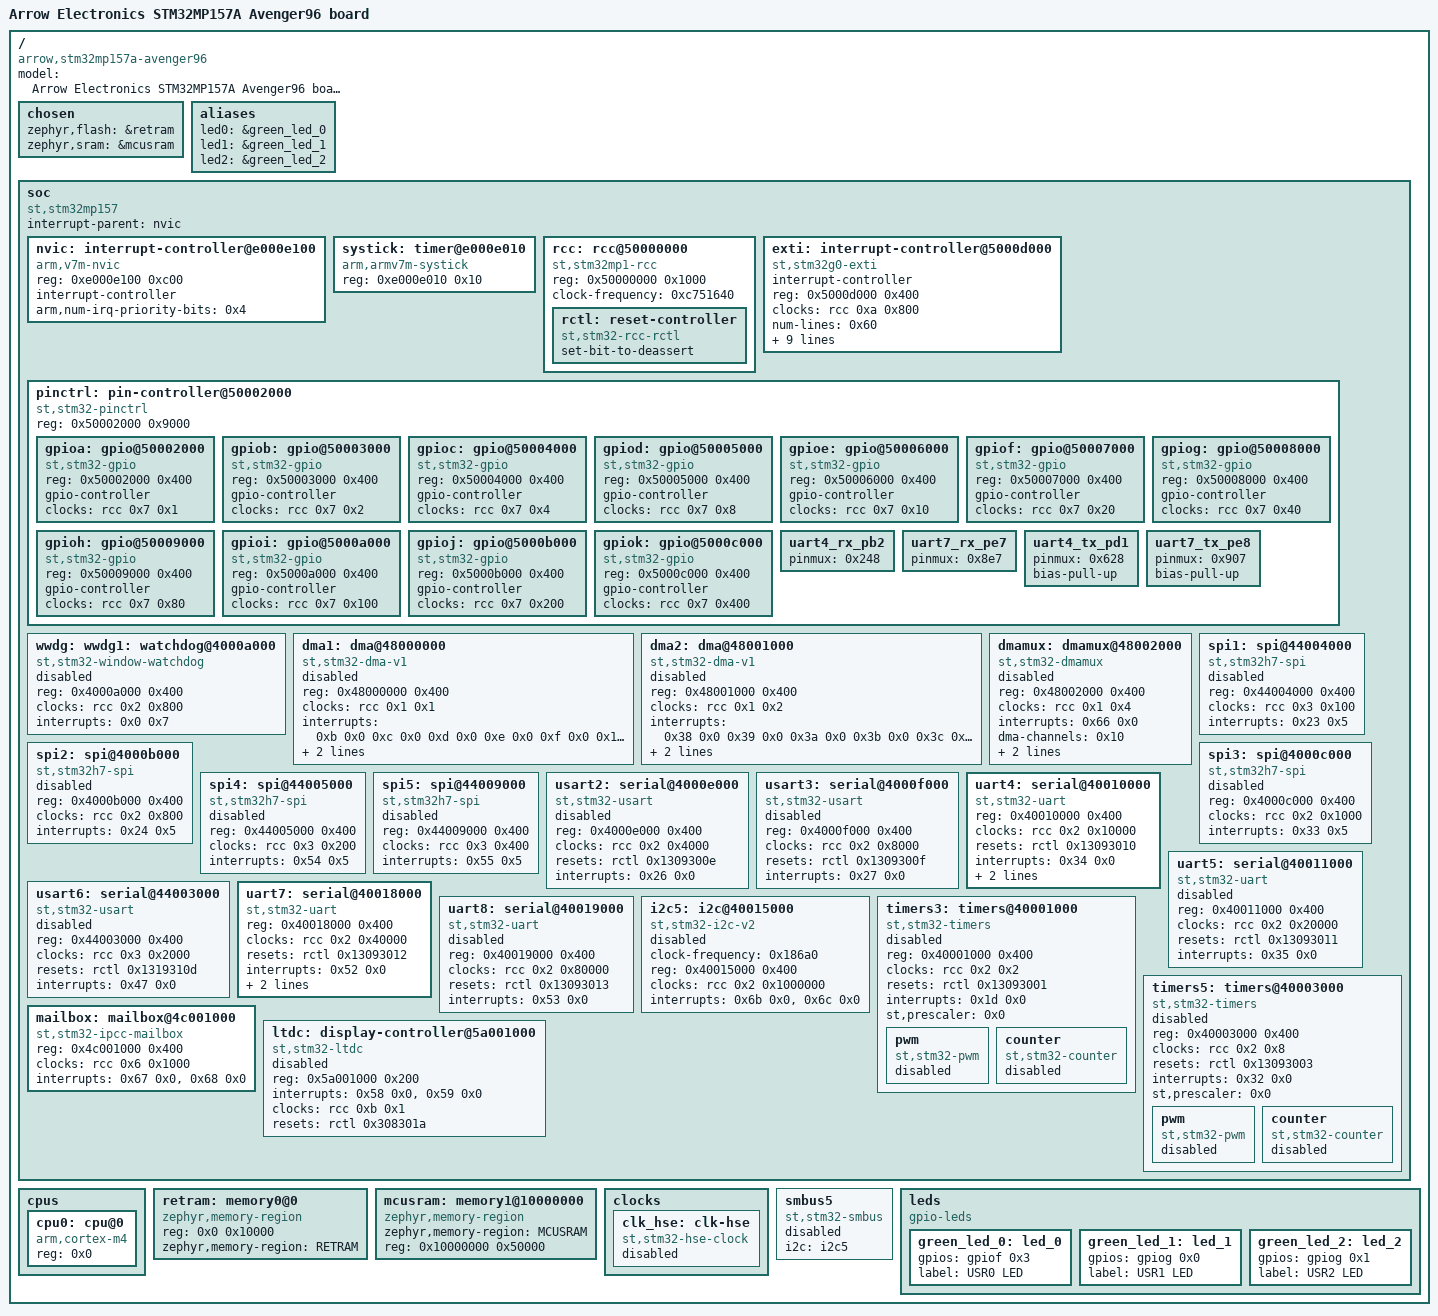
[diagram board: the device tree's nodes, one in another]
/dts-v1/;

/* node '/' defined in zephyr/dts/common/skeleton.dtsi:9 */
/ {
	#address-cells = < 0x1 >;                                /* in zephyr/dts/common/skeleton.dtsi:10 */
	#size-cells = < 0x1 >;                                   /* in zephyr/dts/common/skeleton.dtsi:11 */
	model = "Arrow Electronics STM32MP157A Avenger96 board"; /* in zephyr/boards/96boards/avenger96/96b_avenger96.dts:12 */
	compatible = "arrow,stm32mp157a-avenger96";              /* in zephyr/boards/96boards/avenger96/96b_avenger96.dts:13 */

	/* node '/chosen' defined in zephyr/dts/common/skeleton.dtsi:13 */
	chosen {
		zephyr,flash = &retram; /* in zephyr/boards/96boards/avenger96/96b_avenger96.dts:25 */
		zephyr,sram = &mcusram; /* in zephyr/boards/96boards/avenger96/96b_avenger96.dts:26 */
	};

	/* node '/aliases' defined in zephyr/dts/common/skeleton.dtsi:15 */
	aliases {
		led0 = &green_led_0; /* in zephyr/boards/96boards/avenger96/96b_avenger96.dts:49 */
		led1 = &green_led_1; /* in zephyr/boards/96boards/avenger96/96b_avenger96.dts:50 */
		led2 = &green_led_2; /* in zephyr/boards/96boards/avenger96/96b_avenger96.dts:51 */
	};

	/* node '/soc' defined in zephyr/dts/arm/armv7-m.dtsi:6 */
	soc {
		#address-cells = < 0x1 >;     /* in zephyr/dts/arm/armv7-m.dtsi:7 */
		#size-cells = < 0x1 >;        /* in zephyr/dts/arm/armv7-m.dtsi:8 */
		interrupt-parent = < &nvic >; /* in zephyr/dts/arm/armv7-m.dtsi:10 */
		ranges;                       /* in zephyr/dts/arm/armv7-m.dtsi:11 */
		compatible = "st,stm32mp157",
		             "st,stm32mp1",
		             "simple-bus";    /* in zephyr/dts/arm/st/mp1/stm32mp157.dtsi:55 */

		/* node '/soc/interrupt-controller@e000e100' defined in zephyr/dts/arm/armv7-m.dtsi:13 */
		nvic: interrupt-controller@e000e100 {
			#address-cells = < 0x1 >;            /* in zephyr/dts/arm/armv7-m.dtsi:14 */
			compatible = "arm,v7m-nvic";         /* in zephyr/dts/arm/armv7-m.dtsi:15 */
			reg = < 0xe000e100 0xc00 >;          /* in zephyr/dts/arm/armv7-m.dtsi:16 */
			interrupt-controller;                /* in zephyr/dts/arm/armv7-m.dtsi:17 */
			#interrupt-cells = < 0x2 >;          /* in zephyr/dts/arm/armv7-m.dtsi:18 */
			arm,num-irq-priority-bits = < 0x4 >; /* in zephyr/dts/arm/st/mp1/stm32mp157.dtsi:427 */
			phandle = < 0x1 >;                   /* in zephyr/dts/arm/armv7-m.dtsi:10 */
		};

		/* node '/soc/timer@e000e010' defined in zephyr/dts/arm/armv7-m.dtsi:21 */
		systick: timer@e000e010 {
			compatible = "arm,armv7m-systick"; /* in zephyr/dts/arm/armv7-m.dtsi:22 */
			reg = < 0xe000e010 0x10 >;         /* in zephyr/dts/arm/armv7-m.dtsi:23 */
		};

		/* node '/soc/rcc@50000000' defined in zephyr/dts/arm/st/mp1/stm32mp157.dtsi:57 */
		rcc: rcc@50000000 {
			compatible = "st,stm32mp1-rcc";  /* in zephyr/dts/arm/st/mp1/stm32mp157.dtsi:58 */
			reg = < 0x50000000 0x1000 >;     /* in zephyr/dts/arm/st/mp1/stm32mp157.dtsi:59 */
			#clock-cells = < 0x2 >;          /* in zephyr/dts/arm/st/mp1/stm32mp157.dtsi:60 */
			clock-frequency = < 0xc751640 >; /* in zephyr/boards/96boards/avenger96/96b_avenger96.dts:56 */
			phandle = < 0x2 >;               /* in zephyr/dts/arm/st/mp1/stm32mp157.dtsi:75 */

			/* node '/soc/rcc@50000000/reset-controller' defined in zephyr/dts/arm/st/mp1/stm32mp157.dtsi:62 */
			rctl: reset-controller {
				compatible = "st,stm32-rcc-rctl"; /* in zephyr/dts/arm/st/mp1/stm32mp157.dtsi:63 */
				#reset-cells = < 0x1 >;           /* in zephyr/dts/arm/st/mp1/stm32mp157.dtsi:64 */
				set-bit-to-deassert;              /* in zephyr/dts/arm/st/mp1/stm32mp157.dtsi:65 */
				phandle = < 0x3 >;                /* in zephyr/dts/arm/st/mp1/stm32mp157.dtsi:282 */
			};
		};

		/* node '/soc/interrupt-controller@5000d000' defined in zephyr/dts/arm/st/mp1/stm32mp157.dtsi:69 */
		exti: interrupt-controller@5000d000 {
			compatible = "st,stm32g0-exti",
			             "st,stm32-exti";   /* in zephyr/dts/arm/st/mp1/stm32mp157.dtsi:70 */
			interrupt-controller;           /* in zephyr/dts/arm/st/mp1/stm32mp157.dtsi:71 */
			#interrupt-cells = < 0x1 >;     /* in zephyr/dts/arm/st/mp1/stm32mp157.dtsi:72 */
			#address-cells = < 0x0 >;       /* in zephyr/dts/arm/st/mp1/stm32mp157.dtsi:73 */
			reg = < 0x5000d000 0x400 >;     /* in zephyr/dts/arm/st/mp1/stm32mp157.dtsi:74 */
			clocks = < &rcc 0xa 0x800 >;    /* in zephyr/dts/arm/st/mp1/stm32mp157.dtsi:75 */
			num-lines = < 0x60 >;           /* in zephyr/dts/arm/st/mp1/stm32mp157.dtsi:76 */
			interrupts = < 0x6 0x0 >,
			             < 0x7 0x0 >,
			             < 0x8 0x0 >,
			             < 0x9 0x0 >,
			             < 0xa 0x0 >,
			             < 0x17 0x0 >,
			             < 0x40 0x0 >,
			             < 0x41 0x0 >,
			             < 0x42 0x0 >,
			             < 0x43 0x0 >,
			             < 0x28 0x0 >,
			             < 0x2a 0x0 >,
			             < 0x4c 0x0 >,
			             < 0x4d 0x0 >,
			             < 0x79 0x0 >,
			             < 0x7f 0x0 >;      /* in zephyr/dts/arm/st/mp1/stm32mp157.dtsi:77 */
			interrupt-names = "line0",
			                  "line1",
			                  "line2",
			                  "line3",
			                  "line4",
			                  "line5",
			                  "line6",
			                  "line7",
			                  "line8",
			                  "line9",
			                  "line10",
			                  "line11",
			                  "line12",
			                  "line13",
			                  "line14",
			                  "line15";     /* in zephyr/dts/arm/st/mp1/stm32mp157.dtsi:81 */
			line-ranges = < 0x0 0x1 >,
			              < 0x1 0x1 >,
			              < 0x2 0x1 >,
			              < 0x3 0x1 >,
			              < 0x4 0x1 >,
			              < 0x5 0x1 >,
			              < 0x6 0x1 >,
			              < 0x7 0x1 >,
			              < 0x8 0x1 >,
			              < 0x9 0x1 >,
			              < 0xa 0x1 >,
			              < 0xb 0x1 >,
			              < 0xc 0x1 >,
			              < 0xd 0x1 >,
			              < 0xe 0x1 >,
			              < 0xf 0x1 >;      /* in zephyr/dts/arm/st/mp1/stm32mp157.dtsi:85 */
		};

		/* node '/soc/pin-controller@50002000' defined in zephyr/dts/arm/st/mp1/stm32mp157.dtsi:91 */
		pinctrl: pin-controller@50002000 {
			compatible = "st,stm32-pinctrl"; /* in zephyr/dts/arm/st/mp1/stm32mp157.dtsi:92 */
			reg = < 0x50002000 0x9000 >;     /* in zephyr/dts/arm/st/mp1/stm32mp157.dtsi:93 */
			#address-cells = < 0x1 >;        /* in zephyr/dts/arm/st/mp1/stm32mp157.dtsi:94 */
			#size-cells = < 0x1 >;           /* in zephyr/dts/arm/st/mp1/stm32mp157.dtsi:95 */

			/* node '/soc/pin-controller@50002000/gpio@50002000' defined in zephyr/dts/arm/st/mp1/stm32mp157.dtsi:97 */
			gpioa: gpio@50002000 {
				compatible = "st,stm32-gpio"; /* in zephyr/dts/arm/st/mp1/stm32mp157.dtsi:98 */
				reg = < 0x50002000 0x400 >;   /* in zephyr/dts/arm/st/mp1/stm32mp157.dtsi:99 */
				gpio-controller;              /* in zephyr/dts/arm/st/mp1/stm32mp157.dtsi:100 */
				#gpio-cells = < 0x2 >;        /* in zephyr/dts/arm/st/mp1/stm32mp157.dtsi:101 */
				clocks = < &rcc 0x7 0x1 >;    /* in zephyr/dts/arm/st/mp1/stm32mp157.dtsi:102 */
			};

			/* node '/soc/pin-controller@50002000/gpio@50003000' defined in zephyr/dts/arm/st/mp1/stm32mp157.dtsi:105 */
			gpiob: gpio@50003000 {
				compatible = "st,stm32-gpio"; /* in zephyr/dts/arm/st/mp1/stm32mp157.dtsi:106 */
				reg = < 0x50003000 0x400 >;   /* in zephyr/dts/arm/st/mp1/stm32mp157.dtsi:107 */
				gpio-controller;              /* in zephyr/dts/arm/st/mp1/stm32mp157.dtsi:108 */
				#gpio-cells = < 0x2 >;        /* in zephyr/dts/arm/st/mp1/stm32mp157.dtsi:109 */
				clocks = < &rcc 0x7 0x2 >;    /* in zephyr/dts/arm/st/mp1/stm32mp157.dtsi:110 */
			};

			/* node '/soc/pin-controller@50002000/gpio@50004000' defined in zephyr/dts/arm/st/mp1/stm32mp157.dtsi:113 */
			gpioc: gpio@50004000 {
				compatible = "st,stm32-gpio"; /* in zephyr/dts/arm/st/mp1/stm32mp157.dtsi:114 */
				reg = < 0x50004000 0x400 >;   /* in zephyr/dts/arm/st/mp1/stm32mp157.dtsi:115 */
				gpio-controller;              /* in zephyr/dts/arm/st/mp1/stm32mp157.dtsi:116 */
				#gpio-cells = < 0x2 >;        /* in zephyr/dts/arm/st/mp1/stm32mp157.dtsi:117 */
				clocks = < &rcc 0x7 0x4 >;    /* in zephyr/dts/arm/st/mp1/stm32mp157.dtsi:118 */
			};

			/* node '/soc/pin-controller@50002000/gpio@50005000' defined in zephyr/dts/arm/st/mp1/stm32mp157.dtsi:121 */
			gpiod: gpio@50005000 {
				compatible = "st,stm32-gpio"; /* in zephyr/dts/arm/st/mp1/stm32mp157.dtsi:122 */
				reg = < 0x50005000 0x400 >;   /* in zephyr/dts/arm/st/mp1/stm32mp157.dtsi:123 */
				gpio-controller;              /* in zephyr/dts/arm/st/mp1/stm32mp157.dtsi:124 */
				#gpio-cells = < 0x2 >;        /* in zephyr/dts/arm/st/mp1/stm32mp157.dtsi:125 */
				clocks = < &rcc 0x7 0x8 >;    /* in zephyr/dts/arm/st/mp1/stm32mp157.dtsi:126 */
			};

			/* node '/soc/pin-controller@50002000/gpio@50006000' defined in zephyr/dts/arm/st/mp1/stm32mp157.dtsi:129 */
			gpioe: gpio@50006000 {
				compatible = "st,stm32-gpio"; /* in zephyr/dts/arm/st/mp1/stm32mp157.dtsi:130 */
				reg = < 0x50006000 0x400 >;   /* in zephyr/dts/arm/st/mp1/stm32mp157.dtsi:131 */
				gpio-controller;              /* in zephyr/dts/arm/st/mp1/stm32mp157.dtsi:132 */
				#gpio-cells = < 0x2 >;        /* in zephyr/dts/arm/st/mp1/stm32mp157.dtsi:133 */
				clocks = < &rcc 0x7 0x10 >;   /* in zephyr/dts/arm/st/mp1/stm32mp157.dtsi:134 */
			};

			/* node '/soc/pin-controller@50002000/gpio@50007000' defined in zephyr/dts/arm/st/mp1/stm32mp157.dtsi:137 */
			gpiof: gpio@50007000 {
				compatible = "st,stm32-gpio"; /* in zephyr/dts/arm/st/mp1/stm32mp157.dtsi:138 */
				reg = < 0x50007000 0x400 >;   /* in zephyr/dts/arm/st/mp1/stm32mp157.dtsi:139 */
				gpio-controller;              /* in zephyr/dts/arm/st/mp1/stm32mp157.dtsi:140 */
				#gpio-cells = < 0x2 >;        /* in zephyr/dts/arm/st/mp1/stm32mp157.dtsi:141 */
				clocks = < &rcc 0x7 0x20 >;   /* in zephyr/dts/arm/st/mp1/stm32mp157.dtsi:142 */
				phandle = < 0x9 >;            /* in zephyr/boards/96boards/avenger96/96b_avenger96.dts:33 */
			};

			/* node '/soc/pin-controller@50002000/gpio@50008000' defined in zephyr/dts/arm/st/mp1/stm32mp157.dtsi:145 */
			gpiog: gpio@50008000 {
				compatible = "st,stm32-gpio"; /* in zephyr/dts/arm/st/mp1/stm32mp157.dtsi:146 */
				reg = < 0x50008000 0x400 >;   /* in zephyr/dts/arm/st/mp1/stm32mp157.dtsi:147 */
				gpio-controller;              /* in zephyr/dts/arm/st/mp1/stm32mp157.dtsi:148 */
				#gpio-cells = < 0x2 >;        /* in zephyr/dts/arm/st/mp1/stm32mp157.dtsi:149 */
				clocks = < &rcc 0x7 0x40 >;   /* in zephyr/dts/arm/st/mp1/stm32mp157.dtsi:150 */
				phandle = < 0xa >;            /* in zephyr/boards/96boards/avenger96/96b_avenger96.dts:38 */
			};

			/* node '/soc/pin-controller@50002000/gpio@50009000' defined in zephyr/dts/arm/st/mp1/stm32mp157.dtsi:153 */
			gpioh: gpio@50009000 {
				compatible = "st,stm32-gpio"; /* in zephyr/dts/arm/st/mp1/stm32mp157.dtsi:154 */
				reg = < 0x50009000 0x400 >;   /* in zephyr/dts/arm/st/mp1/stm32mp157.dtsi:155 */
				gpio-controller;              /* in zephyr/dts/arm/st/mp1/stm32mp157.dtsi:156 */
				#gpio-cells = < 0x2 >;        /* in zephyr/dts/arm/st/mp1/stm32mp157.dtsi:157 */
				clocks = < &rcc 0x7 0x80 >;   /* in zephyr/dts/arm/st/mp1/stm32mp157.dtsi:158 */
			};

			/* node '/soc/pin-controller@50002000/gpio@5000a000' defined in zephyr/dts/arm/st/mp1/stm32mp157.dtsi:161 */
			gpioi: gpio@5000a000 {
				compatible = "st,stm32-gpio"; /* in zephyr/dts/arm/st/mp1/stm32mp157.dtsi:162 */
				reg = < 0x5000a000 0x400 >;   /* in zephyr/dts/arm/st/mp1/stm32mp157.dtsi:163 */
				gpio-controller;              /* in zephyr/dts/arm/st/mp1/stm32mp157.dtsi:164 */
				#gpio-cells = < 0x2 >;        /* in zephyr/dts/arm/st/mp1/stm32mp157.dtsi:165 */
				clocks = < &rcc 0x7 0x100 >;  /* in zephyr/dts/arm/st/mp1/stm32mp157.dtsi:166 */
			};

			/* node '/soc/pin-controller@50002000/gpio@5000b000' defined in zephyr/dts/arm/st/mp1/stm32mp157.dtsi:169 */
			gpioj: gpio@5000b000 {
				compatible = "st,stm32-gpio"; /* in zephyr/dts/arm/st/mp1/stm32mp157.dtsi:170 */
				reg = < 0x5000b000 0x400 >;   /* in zephyr/dts/arm/st/mp1/stm32mp157.dtsi:171 */
				gpio-controller;              /* in zephyr/dts/arm/st/mp1/stm32mp157.dtsi:172 */
				#gpio-cells = < 0x2 >;        /* in zephyr/dts/arm/st/mp1/stm32mp157.dtsi:173 */
				clocks = < &rcc 0x7 0x200 >;  /* in zephyr/dts/arm/st/mp1/stm32mp157.dtsi:174 */
			};

			/* node '/soc/pin-controller@50002000/gpio@5000c000' defined in zephyr/dts/arm/st/mp1/stm32mp157.dtsi:177 */
			gpiok: gpio@5000c000 {
				compatible = "st,stm32-gpio"; /* in zephyr/dts/arm/st/mp1/stm32mp157.dtsi:178 */
				reg = < 0x5000c000 0x400 >;   /* in zephyr/dts/arm/st/mp1/stm32mp157.dtsi:179 */
				gpio-controller;              /* in zephyr/dts/arm/st/mp1/stm32mp157.dtsi:180 */
				#gpio-cells = < 0x2 >;        /* in zephyr/dts/arm/st/mp1/stm32mp157.dtsi:181 */
				clocks = < &rcc 0x7 0x400 >;  /* in zephyr/dts/arm/st/mp1/stm32mp157.dtsi:182 */
			};

			/* node '/soc/pin-controller@50002000/uart4_rx_pb2' defined in modules/hal/stm32/dts/st/mp1/stm32mp157aacx-pinctrl.dtsi:5042 */
			uart4_rx_pb2: uart4_rx_pb2 {
				pinmux = < 0x248 >; /* in modules/hal/stm32/dts/st/mp1/stm32mp157aacx-pinctrl.dtsi:5043 */
				phandle = < 0x5 >;  /* in zephyr/boards/96boards/avenger96/96b_avenger96.dts:64 */
			};

			/* node '/soc/pin-controller@50002000/uart7_rx_pe7' defined in modules/hal/stm32/dts/st/mp1/stm32mp157aacx-pinctrl.dtsi:5098 */
			uart7_rx_pe7: uart7_rx_pe7 {
				pinmux = < 0x8e7 >; /* in modules/hal/stm32/dts/st/mp1/stm32mp157aacx-pinctrl.dtsi:5099 */
				phandle = < 0x7 >;  /* in zephyr/boards/96boards/avenger96/96b_avenger96.dts:71 */
			};

			/* node '/soc/pin-controller@50002000/uart4_tx_pd1' defined in modules/hal/stm32/dts/st/mp1/stm32mp157aacx-pinctrl.dtsi:5202 */
			uart4_tx_pd1: uart4_tx_pd1 {
				pinmux = < 0x628 >; /* in modules/hal/stm32/dts/st/mp1/stm32mp157aacx-pinctrl.dtsi:5203 */
				bias-pull-up;       /* in modules/hal/stm32/dts/st/mp1/stm32mp157aacx-pinctrl.dtsi:5204 */
				phandle = < 0x4 >;  /* in zephyr/boards/96boards/avenger96/96b_avenger96.dts:64 */
			};

			/* node '/soc/pin-controller@50002000/uart7_tx_pe8' defined in modules/hal/stm32/dts/st/mp1/stm32mp157aacx-pinctrl.dtsi:5252 */
			uart7_tx_pe8: uart7_tx_pe8 {
				pinmux = < 0x907 >; /* in modules/hal/stm32/dts/st/mp1/stm32mp157aacx-pinctrl.dtsi:5253 */
				bias-pull-up;       /* in modules/hal/stm32/dts/st/mp1/stm32mp157aacx-pinctrl.dtsi:5254 */
				phandle = < 0x6 >;  /* in zephyr/boards/96boards/avenger96/96b_avenger96.dts:71 */
			};
		};

		/* node '/soc/watchdog@4000a000' defined in zephyr/dts/arm/st/mp1/stm32mp157.dtsi:186 */
		wwdg: wwdg1: watchdog@4000a000 {
			compatible = "st,stm32-window-watchdog"; /* in zephyr/dts/arm/st/mp1/stm32mp157.dtsi:187 */
			reg = < 0x4000a000 0x400 >;              /* in zephyr/dts/arm/st/mp1/stm32mp157.dtsi:188 */
			clocks = < &rcc 0x2 0x800 >;             /* in zephyr/dts/arm/st/mp1/stm32mp157.dtsi:189 */
			interrupts = < 0x0 0x7 >;                /* in zephyr/dts/arm/st/mp1/stm32mp157.dtsi:190 */
			status = "disabled";                     /* in zephyr/dts/arm/st/mp1/stm32mp157.dtsi:191 */
		};

		/* node '/soc/dma@48000000' defined in zephyr/dts/arm/st/mp1/stm32mp157.dtsi:194 */
		dma1: dma@48000000 {
			compatible = "st,stm32-dma-v1";                                                      /* in zephyr/dts/arm/st/mp1/stm32mp157.dtsi:195 */
			#dma-cells = < 0x4 >;                                                                /* in zephyr/dts/arm/st/mp1/stm32mp157.dtsi:196 */
			reg = < 0x48000000 0x400 >;                                                          /* in zephyr/dts/arm/st/mp1/stm32mp157.dtsi:197 */
			clocks = < &rcc 0x1 0x1 >;                                                           /* in zephyr/dts/arm/st/mp1/stm32mp157.dtsi:198 */
			interrupts = < 0xb 0x0 0xc 0x0 0xd 0x0 0xe 0x0 0xf 0x0 0x10 0x0 0x11 0x0 0x2f 0x0 >; /* in zephyr/dts/arm/st/mp1/stm32mp157.dtsi:199 */
			dma-offset = < 0x0 >;                                                                /* in zephyr/dts/arm/st/mp1/stm32mp157.dtsi:200 */
			dma-requests = < 0x8 >;                                                              /* in zephyr/dts/arm/st/mp1/stm32mp157.dtsi:201 */
			status = "disabled";                                                                 /* in zephyr/dts/arm/st/mp1/stm32mp157.dtsi:202 */
		};

		/* node '/soc/dma@48001000' defined in zephyr/dts/arm/st/mp1/stm32mp157.dtsi:205 */
		dma2: dma@48001000 {
			compatible = "st,stm32-dma-v1";                                                           /* in zephyr/dts/arm/st/mp1/stm32mp157.dtsi:206 */
			#dma-cells = < 0x4 >;                                                                     /* in zephyr/dts/arm/st/mp1/stm32mp157.dtsi:207 */
			reg = < 0x48001000 0x400 >;                                                               /* in zephyr/dts/arm/st/mp1/stm32mp157.dtsi:208 */
			clocks = < &rcc 0x1 0x2 >;                                                                /* in zephyr/dts/arm/st/mp1/stm32mp157.dtsi:209 */
			interrupts = < 0x38 0x0 0x39 0x0 0x3a 0x0 0x3b 0x0 0x3c 0x0 0x44 0x0 0x45 0x0 0x46 0x0 >; /* in zephyr/dts/arm/st/mp1/stm32mp157.dtsi:210 */
			dma-offset = < 0x8 >;                                                                     /* in zephyr/dts/arm/st/mp1/stm32mp157.dtsi:211 */
			dma-requests = < 0x8 >;                                                                   /* in zephyr/dts/arm/st/mp1/stm32mp157.dtsi:212 */
			status = "disabled";                                                                      /* in zephyr/dts/arm/st/mp1/stm32mp157.dtsi:213 */
		};

		/* node '/soc/dmamux@48002000' defined in zephyr/dts/arm/st/mp1/stm32mp157.dtsi:216 */
		dmamux: dmamux@48002000 {
			compatible = "st,stm32-dmamux"; /* in zephyr/dts/arm/st/mp1/stm32mp157.dtsi:217 */
			#dma-cells = < 0x3 >;           /* in zephyr/dts/arm/st/mp1/stm32mp157.dtsi:218 */
			reg = < 0x48002000 0x400 >;     /* in zephyr/dts/arm/st/mp1/stm32mp157.dtsi:219 */
			clocks = < &rcc 0x1 0x4 >;      /* in zephyr/dts/arm/st/mp1/stm32mp157.dtsi:220 */
			interrupts = < 0x66 0x0 >;      /* in zephyr/dts/arm/st/mp1/stm32mp157.dtsi:221 */
			dma-channels = < 0x10 >;        /* in zephyr/dts/arm/st/mp1/stm32mp157.dtsi:222 */
			dma-generators = < 0x8 >;       /* in zephyr/dts/arm/st/mp1/stm32mp157.dtsi:223 */
			dma-requests = < 0x6c >;        /* in zephyr/dts/arm/st/mp1/stm32mp157.dtsi:224 */
			status = "disabled";            /* in zephyr/dts/arm/st/mp1/stm32mp157.dtsi:225 */
		};

		/* node '/soc/spi@44004000' defined in zephyr/dts/arm/st/mp1/stm32mp157.dtsi:228 */
		spi1: spi@44004000 {
			compatible = "st,stm32h7-spi",
			             "st,stm32-spi-fifo",
			             "st,stm32-spi";      /* in zephyr/dts/arm/st/mp1/stm32mp157.dtsi:229 */
			reg = < 0x44004000 0x400 >;       /* in zephyr/dts/arm/st/mp1/stm32mp157.dtsi:230 */
			#address-cells = < 0x1 >;         /* in zephyr/dts/arm/st/mp1/stm32mp157.dtsi:231 */
			#size-cells = < 0x0 >;            /* in zephyr/dts/arm/st/mp1/stm32mp157.dtsi:232 */
			clocks = < &rcc 0x3 0x100 >;      /* in zephyr/dts/arm/st/mp1/stm32mp157.dtsi:233 */
			interrupts = < 0x23 0x5 >;        /* in zephyr/dts/arm/st/mp1/stm32mp157.dtsi:234 */
			status = "disabled";              /* in zephyr/dts/arm/st/mp1/stm32mp157.dtsi:235 */
		};

		/* node '/soc/spi@4000b000' defined in zephyr/dts/arm/st/mp1/stm32mp157.dtsi:238 */
		spi2: spi@4000b000 {
			compatible = "st,stm32h7-spi",
			             "st,stm32-spi-fifo",
			             "st,stm32-spi";      /* in zephyr/dts/arm/st/mp1/stm32mp157.dtsi:239 */
			reg = < 0x4000b000 0x400 >;       /* in zephyr/dts/arm/st/mp1/stm32mp157.dtsi:240 */
			#address-cells = < 0x1 >;         /* in zephyr/dts/arm/st/mp1/stm32mp157.dtsi:241 */
			#size-cells = < 0x0 >;            /* in zephyr/dts/arm/st/mp1/stm32mp157.dtsi:242 */
			clocks = < &rcc 0x2 0x800 >;      /* in zephyr/dts/arm/st/mp1/stm32mp157.dtsi:243 */
			interrupts = < 0x24 0x5 >;        /* in zephyr/dts/arm/st/mp1/stm32mp157.dtsi:244 */
			status = "disabled";              /* in zephyr/dts/arm/st/mp1/stm32mp157.dtsi:245 */
		};

		/* node '/soc/spi@4000c000' defined in zephyr/dts/arm/st/mp1/stm32mp157.dtsi:248 */
		spi3: spi@4000c000 {
			compatible = "st,stm32h7-spi",
			             "st,stm32-spi-fifo",
			             "st,stm32-spi";      /* in zephyr/dts/arm/st/mp1/stm32mp157.dtsi:249 */
			reg = < 0x4000c000 0x400 >;       /* in zephyr/dts/arm/st/mp1/stm32mp157.dtsi:250 */
			#address-cells = < 0x1 >;         /* in zephyr/dts/arm/st/mp1/stm32mp157.dtsi:251 */
			#size-cells = < 0x0 >;            /* in zephyr/dts/arm/st/mp1/stm32mp157.dtsi:252 */
			clocks = < &rcc 0x2 0x1000 >;     /* in zephyr/dts/arm/st/mp1/stm32mp157.dtsi:253 */
			interrupts = < 0x33 0x5 >;        /* in zephyr/dts/arm/st/mp1/stm32mp157.dtsi:254 */
			status = "disabled";              /* in zephyr/dts/arm/st/mp1/stm32mp157.dtsi:255 */
		};

		/* node '/soc/spi@44005000' defined in zephyr/dts/arm/st/mp1/stm32mp157.dtsi:258 */
		spi4: spi@44005000 {
			compatible = "st,stm32h7-spi",
			             "st,stm32-spi-fifo",
			             "st,stm32-spi";      /* in zephyr/dts/arm/st/mp1/stm32mp157.dtsi:259 */
			reg = < 0x44005000 0x400 >;       /* in zephyr/dts/arm/st/mp1/stm32mp157.dtsi:260 */
			#address-cells = < 0x1 >;         /* in zephyr/dts/arm/st/mp1/stm32mp157.dtsi:261 */
			#size-cells = < 0x0 >;            /* in zephyr/dts/arm/st/mp1/stm32mp157.dtsi:262 */
			clocks = < &rcc 0x3 0x200 >;      /* in zephyr/dts/arm/st/mp1/stm32mp157.dtsi:263 */
			interrupts = < 0x54 0x5 >;        /* in zephyr/dts/arm/st/mp1/stm32mp157.dtsi:264 */
			status = "disabled";              /* in zephyr/dts/arm/st/mp1/stm32mp157.dtsi:265 */
		};

		/* node '/soc/spi@44009000' defined in zephyr/dts/arm/st/mp1/stm32mp157.dtsi:268 */
		spi5: spi@44009000 {
			compatible = "st,stm32h7-spi",
			             "st,stm32-spi-fifo",
			             "st,stm32-spi";      /* in zephyr/dts/arm/st/mp1/stm32mp157.dtsi:269 */
			reg = < 0x44009000 0x400 >;       /* in zephyr/dts/arm/st/mp1/stm32mp157.dtsi:270 */
			#address-cells = < 0x1 >;         /* in zephyr/dts/arm/st/mp1/stm32mp157.dtsi:271 */
			#size-cells = < 0x0 >;            /* in zephyr/dts/arm/st/mp1/stm32mp157.dtsi:272 */
			clocks = < &rcc 0x3 0x400 >;      /* in zephyr/dts/arm/st/mp1/stm32mp157.dtsi:273 */
			interrupts = < 0x55 0x5 >;        /* in zephyr/dts/arm/st/mp1/stm32mp157.dtsi:274 */
			status = "disabled";              /* in zephyr/dts/arm/st/mp1/stm32mp157.dtsi:275 */
		};

		/* node '/soc/serial@4000e000' defined in zephyr/dts/arm/st/mp1/stm32mp157.dtsi:278 */
		usart2: serial@4000e000 {
			compatible = "st,stm32-usart",
			             "st,stm32-uart";  /* in zephyr/dts/arm/st/mp1/stm32mp157.dtsi:279 */
			reg = < 0x4000e000 0x400 >;    /* in zephyr/dts/arm/st/mp1/stm32mp157.dtsi:280 */
			clocks = < &rcc 0x2 0x4000 >;  /* in zephyr/dts/arm/st/mp1/stm32mp157.dtsi:281 */
			resets = < &rctl 0x1309300e >; /* in zephyr/dts/arm/st/mp1/stm32mp157.dtsi:282 */
			interrupts = < 0x26 0x0 >;     /* in zephyr/dts/arm/st/mp1/stm32mp157.dtsi:283 */
			status = "disabled";           /* in zephyr/dts/arm/st/mp1/stm32mp157.dtsi:284 */
		};

		/* node '/soc/serial@4000f000' defined in zephyr/dts/arm/st/mp1/stm32mp157.dtsi:287 */
		usart3: serial@4000f000 {
			compatible = "st,stm32-usart",
			             "st,stm32-uart";  /* in zephyr/dts/arm/st/mp1/stm32mp157.dtsi:288 */
			reg = < 0x4000f000 0x400 >;    /* in zephyr/dts/arm/st/mp1/stm32mp157.dtsi:289 */
			clocks = < &rcc 0x2 0x8000 >;  /* in zephyr/dts/arm/st/mp1/stm32mp157.dtsi:290 */
			resets = < &rctl 0x1309300f >; /* in zephyr/dts/arm/st/mp1/stm32mp157.dtsi:291 */
			interrupts = < 0x27 0x0 >;     /* in zephyr/dts/arm/st/mp1/stm32mp157.dtsi:292 */
			status = "disabled";           /* in zephyr/dts/arm/st/mp1/stm32mp157.dtsi:293 */
		};

		/* node '/soc/serial@40010000' defined in zephyr/dts/arm/st/mp1/stm32mp157.dtsi:296 */
		uart4: serial@40010000 {
			compatible = "st,stm32-uart";                /* in zephyr/dts/arm/st/mp1/stm32mp157.dtsi:297 */
			reg = < 0x40010000 0x400 >;                  /* in zephyr/dts/arm/st/mp1/stm32mp157.dtsi:298 */
			clocks = < &rcc 0x2 0x10000 >;               /* in zephyr/dts/arm/st/mp1/stm32mp157.dtsi:299 */
			resets = < &rctl 0x13093010 >;               /* in zephyr/dts/arm/st/mp1/stm32mp157.dtsi:300 */
			interrupts = < 0x34 0x0 >;                   /* in zephyr/dts/arm/st/mp1/stm32mp157.dtsi:301 */
			pinctrl-0 = < &uart4_tx_pd1 &uart4_rx_pb2 >; /* in zephyr/boards/96boards/avenger96/96b_avenger96.dts:64 */
			pinctrl-names = "default";                   /* in zephyr/boards/96boards/avenger96/96b_avenger96.dts:65 */
			current-speed = < 0x1c200 >;                 /* in zephyr/boards/96boards/avenger96/96b_avenger96.dts:66 */
			status = "okay";                             /* in zephyr/boards/96boards/avenger96/96b_avenger96.dts:67 */
		};

		/* node '/soc/serial@40011000' defined in zephyr/dts/arm/st/mp1/stm32mp157.dtsi:305 */
		uart5: serial@40011000 {
			compatible = "st,stm32-uart";  /* in zephyr/dts/arm/st/mp1/stm32mp157.dtsi:306 */
			reg = < 0x40011000 0x400 >;    /* in zephyr/dts/arm/st/mp1/stm32mp157.dtsi:307 */
			clocks = < &rcc 0x2 0x20000 >; /* in zephyr/dts/arm/st/mp1/stm32mp157.dtsi:308 */
			resets = < &rctl 0x13093011 >; /* in zephyr/dts/arm/st/mp1/stm32mp157.dtsi:309 */
			interrupts = < 0x35 0x0 >;     /* in zephyr/dts/arm/st/mp1/stm32mp157.dtsi:310 */
			status = "disabled";           /* in zephyr/dts/arm/st/mp1/stm32mp157.dtsi:311 */
		};

		/* node '/soc/serial@44003000' defined in zephyr/dts/arm/st/mp1/stm32mp157.dtsi:314 */
		usart6: serial@44003000 {
			compatible = "st,stm32-usart",
			             "st,stm32-uart";  /* in zephyr/dts/arm/st/mp1/stm32mp157.dtsi:315 */
			reg = < 0x44003000 0x400 >;    /* in zephyr/dts/arm/st/mp1/stm32mp157.dtsi:316 */
			clocks = < &rcc 0x3 0x2000 >;  /* in zephyr/dts/arm/st/mp1/stm32mp157.dtsi:317 */
			resets = < &rctl 0x1319310d >; /* in zephyr/dts/arm/st/mp1/stm32mp157.dtsi:318 */
			interrupts = < 0x47 0x0 >;     /* in zephyr/dts/arm/st/mp1/stm32mp157.dtsi:319 */
			status = "disabled";           /* in zephyr/dts/arm/st/mp1/stm32mp157.dtsi:320 */
		};

		/* node '/soc/serial@40018000' defined in zephyr/dts/arm/st/mp1/stm32mp157.dtsi:323 */
		uart7: serial@40018000 {
			compatible = "st,stm32-uart";                /* in zephyr/dts/arm/st/mp1/stm32mp157.dtsi:324 */
			reg = < 0x40018000 0x400 >;                  /* in zephyr/dts/arm/st/mp1/stm32mp157.dtsi:325 */
			clocks = < &rcc 0x2 0x40000 >;               /* in zephyr/dts/arm/st/mp1/stm32mp157.dtsi:326 */
			resets = < &rctl 0x13093012 >;               /* in zephyr/dts/arm/st/mp1/stm32mp157.dtsi:327 */
			interrupts = < 0x52 0x0 >;                   /* in zephyr/dts/arm/st/mp1/stm32mp157.dtsi:328 */
			pinctrl-0 = < &uart7_tx_pe8 &uart7_rx_pe7 >; /* in zephyr/boards/96boards/avenger96/96b_avenger96.dts:71 */
			pinctrl-names = "default";                   /* in zephyr/boards/96boards/avenger96/96b_avenger96.dts:72 */
			current-speed = < 0x1c200 >;                 /* in zephyr/boards/96boards/avenger96/96b_avenger96.dts:73 */
			status = "okay";                             /* in zephyr/boards/96boards/avenger96/96b_avenger96.dts:74 */
		};

		/* node '/soc/serial@40019000' defined in zephyr/dts/arm/st/mp1/stm32mp157.dtsi:332 */
		uart8: serial@40019000 {
			compatible = "st,stm32-uart";  /* in zephyr/dts/arm/st/mp1/stm32mp157.dtsi:333 */
			reg = < 0x40019000 0x400 >;    /* in zephyr/dts/arm/st/mp1/stm32mp157.dtsi:334 */
			clocks = < &rcc 0x2 0x80000 >; /* in zephyr/dts/arm/st/mp1/stm32mp157.dtsi:335 */
			resets = < &rctl 0x13093013 >; /* in zephyr/dts/arm/st/mp1/stm32mp157.dtsi:336 */
			interrupts = < 0x53 0x0 >;     /* in zephyr/dts/arm/st/mp1/stm32mp157.dtsi:337 */
			status = "disabled";           /* in zephyr/dts/arm/st/mp1/stm32mp157.dtsi:338 */
		};

		/* node '/soc/i2c@40015000' defined in zephyr/dts/arm/st/mp1/stm32mp157.dtsi:341 */
		i2c5: i2c@40015000 {
			compatible = "st,stm32-i2c-v2";  /* in zephyr/dts/arm/st/mp1/stm32mp157.dtsi:342 */
			clock-frequency = < 0x186a0 >;   /* in zephyr/dts/arm/st/mp1/stm32mp157.dtsi:343 */
			reg = < 0x40015000 0x400 >;      /* in zephyr/dts/arm/st/mp1/stm32mp157.dtsi:344 */
			#address-cells = < 0x1 >;        /* in zephyr/dts/arm/st/mp1/stm32mp157.dtsi:345 */
			#size-cells = < 0x0 >;           /* in zephyr/dts/arm/st/mp1/stm32mp157.dtsi:346 */
			clocks = < &rcc 0x2 0x1000000 >; /* in zephyr/dts/arm/st/mp1/stm32mp157.dtsi:347 */
			interrupt-names = "event",
			                  "error";       /* in zephyr/dts/arm/st/mp1/stm32mp157.dtsi:348 */
			interrupts = < 0x6b 0x0 >,
			             < 0x6c 0x0 >;       /* in zephyr/dts/arm/st/mp1/stm32mp157.dtsi:349 */
			status = "disabled";             /* in zephyr/dts/arm/st/mp1/stm32mp157.dtsi:350 */
			phandle = < 0x8 >;               /* in zephyr/dts/arm/st/mp1/stm32mp157.dtsi:421 */
		};

		/* node '/soc/timers@40001000' defined in zephyr/dts/arm/st/mp1/stm32mp157.dtsi:353 */
		timers3: timers@40001000 {
			compatible = "st,stm32-timers"; /* in zephyr/dts/arm/st/mp1/stm32mp157.dtsi:354 */
			reg = < 0x40001000 0x400 >;     /* in zephyr/dts/arm/st/mp1/stm32mp157.dtsi:355 */
			clocks = < &rcc 0x2 0x2 >;      /* in zephyr/dts/arm/st/mp1/stm32mp157.dtsi:356 */
			resets = < &rctl 0x13093001 >;  /* in zephyr/dts/arm/st/mp1/stm32mp157.dtsi:357 */
			interrupts = < 0x1d 0x0 >;      /* in zephyr/dts/arm/st/mp1/stm32mp157.dtsi:358 */
			interrupt-names = "global";     /* in zephyr/dts/arm/st/mp1/stm32mp157.dtsi:359 */
			st,prescaler = < 0x0 >;         /* in zephyr/dts/arm/st/mp1/stm32mp157.dtsi:360 */
			status = "disabled";            /* in zephyr/dts/arm/st/mp1/stm32mp157.dtsi:361 */

			/* node '/soc/timers@40001000/pwm' defined in zephyr/dts/arm/st/mp1/stm32mp157.dtsi:363 */
			pwm {
				compatible = "st,stm32-pwm"; /* in zephyr/dts/arm/st/mp1/stm32mp157.dtsi:364 */
				status = "disabled";         /* in zephyr/dts/arm/st/mp1/stm32mp157.dtsi:365 */
				#pwm-cells = < 0x3 >;        /* in zephyr/dts/arm/st/mp1/stm32mp157.dtsi:366 */
			};

			/* node '/soc/timers@40001000/counter' defined in zephyr/dts/arm/st/mp1/stm32mp157.dtsi:369 */
			counter {
				compatible = "st,stm32-counter"; /* in zephyr/dts/arm/st/mp1/stm32mp157.dtsi:370 */
				status = "disabled";             /* in zephyr/dts/arm/st/mp1/stm32mp157.dtsi:371 */
			};
		};

		/* node '/soc/timers@40003000' defined in zephyr/dts/arm/st/mp1/stm32mp157.dtsi:375 */
		timers5: timers@40003000 {
			compatible = "st,stm32-timers"; /* in zephyr/dts/arm/st/mp1/stm32mp157.dtsi:376 */
			reg = < 0x40003000 0x400 >;     /* in zephyr/dts/arm/st/mp1/stm32mp157.dtsi:377 */
			clocks = < &rcc 0x2 0x8 >;      /* in zephyr/dts/arm/st/mp1/stm32mp157.dtsi:378 */
			resets = < &rctl 0x13093003 >;  /* in zephyr/dts/arm/st/mp1/stm32mp157.dtsi:379 */
			interrupts = < 0x32 0x0 >;      /* in zephyr/dts/arm/st/mp1/stm32mp157.dtsi:380 */
			interrupt-names = "global";     /* in zephyr/dts/arm/st/mp1/stm32mp157.dtsi:381 */
			st,prescaler = < 0x0 >;         /* in zephyr/dts/arm/st/mp1/stm32mp157.dtsi:382 */
			status = "disabled";            /* in zephyr/dts/arm/st/mp1/stm32mp157.dtsi:383 */

			/* node '/soc/timers@40003000/pwm' defined in zephyr/dts/arm/st/mp1/stm32mp157.dtsi:385 */
			pwm {
				compatible = "st,stm32-pwm"; /* in zephyr/dts/arm/st/mp1/stm32mp157.dtsi:386 */
				status = "disabled";         /* in zephyr/dts/arm/st/mp1/stm32mp157.dtsi:387 */
				#pwm-cells = < 0x3 >;        /* in zephyr/dts/arm/st/mp1/stm32mp157.dtsi:388 */
			};

			/* node '/soc/timers@40003000/counter' defined in zephyr/dts/arm/st/mp1/stm32mp157.dtsi:391 */
			counter {
				compatible = "st,stm32-counter"; /* in zephyr/dts/arm/st/mp1/stm32mp157.dtsi:392 */
				status = "disabled";             /* in zephyr/dts/arm/st/mp1/stm32mp157.dtsi:393 */
			};
		};

		/* node '/soc/mailbox@4c001000' defined in zephyr/dts/arm/st/mp1/stm32mp157.dtsi:397 */
		mailbox: mailbox@4c001000 {
			compatible = "st,stm32-ipcc-mailbox"; /* in zephyr/dts/arm/st/mp1/stm32mp157.dtsi:398 */
			reg = < 0x4c001000 0x400 >;           /* in zephyr/dts/arm/st/mp1/stm32mp157.dtsi:399 */
			clocks = < &rcc 0x6 0x1000 >;         /* in zephyr/dts/arm/st/mp1/stm32mp157.dtsi:400 */
			interrupts = < 0x67 0x0 >,
			             < 0x68 0x0 >;            /* in zephyr/dts/arm/st/mp1/stm32mp157.dtsi:401 */
			interrupt-names = "rxo",
			                  "txf";              /* in zephyr/dts/arm/st/mp1/stm32mp157.dtsi:402 */
			status = "okay";                      /* in zephyr/boards/96boards/avenger96/96b_avenger96.dts:60 */
		};

		/* node '/soc/display-controller@5a001000' defined in zephyr/dts/arm/st/mp1/stm32mp157.dtsi:406 */
		ltdc: display-controller@5a001000 {
			compatible = "st,stm32-ltdc"; /* in zephyr/dts/arm/st/mp1/stm32mp157.dtsi:407 */
			reg = < 0x5a001000 0x200 >;   /* in zephyr/dts/arm/st/mp1/stm32mp157.dtsi:408 */
			interrupts = < 0x58 0x0 >,
			             < 0x59 0x0 >;    /* in zephyr/dts/arm/st/mp1/stm32mp157.dtsi:409 */
			interrupt-names = "ltdc",
			                  "ltdc_er";  /* in zephyr/dts/arm/st/mp1/stm32mp157.dtsi:410 */
			clocks = < &rcc 0xb 0x1 >;    /* in zephyr/dts/arm/st/mp1/stm32mp157.dtsi:411 */
			resets = < &rctl 0x308301a >; /* in zephyr/dts/arm/st/mp1/stm32mp157.dtsi:412 */
			status = "disabled";          /* in zephyr/dts/arm/st/mp1/stm32mp157.dtsi:413 */
		};
	};

	/* node '/cpus' defined in zephyr/dts/arm/st/mp1/stm32mp157.dtsi:22 */
	cpus {
		#address-cells = < 0x1 >; /* in zephyr/dts/arm/st/mp1/stm32mp157.dtsi:23 */
		#size-cells = < 0x0 >;    /* in zephyr/dts/arm/st/mp1/stm32mp157.dtsi:24 */

		/* node '/cpus/cpu@0' defined in zephyr/dts/arm/st/mp1/stm32mp157.dtsi:26 */
		cpu0: cpu@0 {
			device_type = "cpu";          /* in zephyr/dts/arm/st/mp1/stm32mp157.dtsi:27 */
			compatible = "arm,cortex-m4"; /* in zephyr/dts/arm/st/mp1/stm32mp157.dtsi:28 */
			reg = < 0x0 >;                /* in zephyr/dts/arm/st/mp1/stm32mp157.dtsi:29 */
		};
	};

	/* node '/memory0@0' defined in zephyr/dts/arm/st/mp1/stm32mp157.dtsi:33 */
	retram: memory0@0 {
		compatible = "zephyr,memory-region",
		             "mmio-sram";            /* in zephyr/dts/arm/st/mp1/stm32mp157.dtsi:34 */
		reg = < 0x0 0x10000 >;               /* in zephyr/dts/arm/st/mp1/stm32mp157.dtsi:35 */
		zephyr,memory-region = "RETRAM";     /* in zephyr/dts/arm/st/mp1/stm32mp157.dtsi:36 */
	};

	/* node '/memory1@10000000' defined in zephyr/dts/arm/st/mp1/stm32mp157.dtsi:39 */
	mcusram: memory1@10000000 {
		compatible = "zephyr,memory-region",
		             "mmio-sram";            /* in zephyr/dts/arm/st/mp1/stm32mp157.dtsi:40 */
		zephyr,memory-region = "MCUSRAM";    /* in zephyr/dts/arm/st/mp1/stm32mp157.dtsi:41 */
		reg = < 0x10000000 0x50000 >;        /* in zephyr/dts/arm/st/mp1/stm32mp157.dtsi:42 */
	};

	/* node '/clocks' defined in zephyr/dts/arm/st/mp1/stm32mp157.dtsi:45 */
	clocks {

		/* node '/clocks/clk-hse' defined in zephyr/dts/arm/st/mp1/stm32mp157.dtsi:47 */
		clk_hse: clk-hse {
			#clock-cells = < 0x0 >;            /* in zephyr/dts/arm/st/mp1/stm32mp157.dtsi:48 */
			compatible = "st,stm32-hse-clock"; /* in zephyr/dts/arm/st/mp1/stm32mp157.dtsi:49 */
			status = "disabled";               /* in zephyr/dts/arm/st/mp1/stm32mp157.dtsi:50 */
		};
	};

	/* node '/smbus5' defined in zephyr/dts/arm/st/mp1/stm32mp157.dtsi:417 */
	smbus5: smbus5 {
		compatible = "st,stm32-smbus"; /* in zephyr/dts/arm/st/mp1/stm32mp157.dtsi:418 */
		#address-cells = < 0x1 >;      /* in zephyr/dts/arm/st/mp1/stm32mp157.dtsi:419 */
		#size-cells = < 0x0 >;         /* in zephyr/dts/arm/st/mp1/stm32mp157.dtsi:420 */
		i2c = < &i2c5 >;               /* in zephyr/dts/arm/st/mp1/stm32mp157.dtsi:421 */
		status = "disabled";           /* in zephyr/dts/arm/st/mp1/stm32mp157.dtsi:422 */
	};

	/* node '/leds' defined in zephyr/boards/96boards/avenger96/96b_avenger96.dts:29 */
	leds {
		compatible = "gpio-leds"; /* in zephyr/boards/96boards/avenger96/96b_avenger96.dts:30 */

		/* node '/leds/led_0' defined in zephyr/boards/96boards/avenger96/96b_avenger96.dts:32 */
		green_led_0: led_0 {
			gpios = < &gpiof 0x3 0x0 >; /* in zephyr/boards/96boards/avenger96/96b_avenger96.dts:33 */
			label = "USR0 LED";         /* in zephyr/boards/96boards/avenger96/96b_avenger96.dts:34 */
		};

		/* node '/leds/led_1' defined in zephyr/boards/96boards/avenger96/96b_avenger96.dts:37 */
		green_led_1: led_1 {
			gpios = < &gpiog 0x0 0x0 >; /* in zephyr/boards/96boards/avenger96/96b_avenger96.dts:38 */
			label = "USR1 LED";         /* in zephyr/boards/96boards/avenger96/96b_avenger96.dts:39 */
		};

		/* node '/leds/led_2' defined in zephyr/boards/96boards/avenger96/96b_avenger96.dts:42 */
		green_led_2: led_2 {
			gpios = < &gpiog 0x1 0x0 >; /* in zephyr/boards/96boards/avenger96/96b_avenger96.dts:43 */
			label = "USR2 LED";         /* in zephyr/boards/96boards/avenger96/96b_avenger96.dts:44 */
		};
	};
};
